AUTOSAR XML (schema 4-2-2)
package /STELLANTIS/EPT/ASWCs
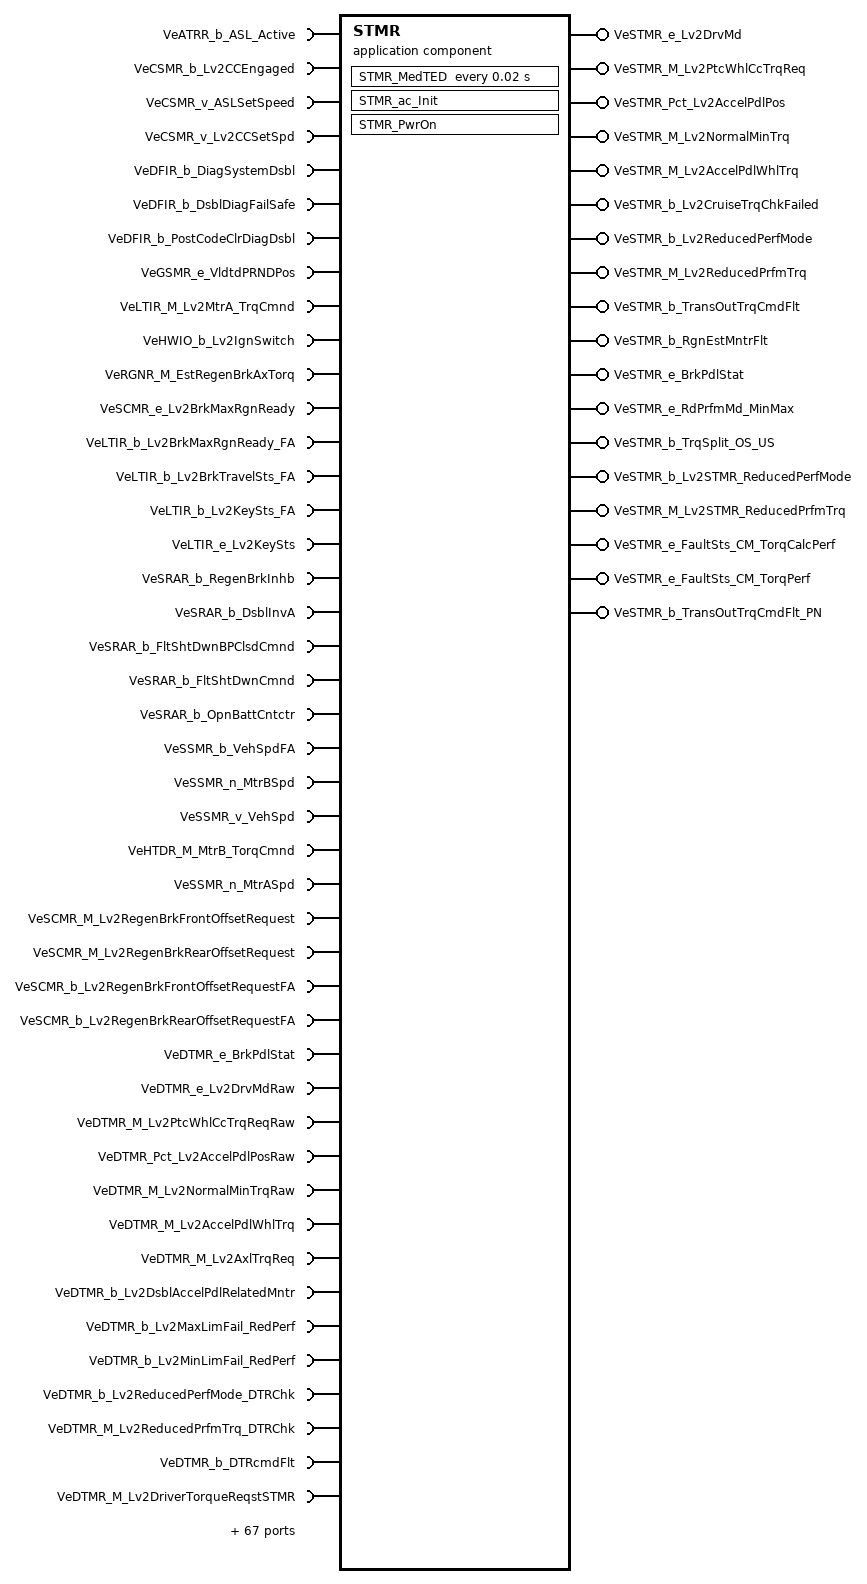
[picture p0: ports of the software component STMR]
  application sw component type STMR
    109 x require port:
      VeATRR_b_ASL_Active: nonqueued-receiver-com-spec{data-element=Value, init-value=0}, required-interface=VeATRR_b_ASL_Active
      VeCSMR_b_Lv2CCEngaged: nonqueued-receiver-com-spec{data-element=Value, init-value=0}, required-interface=VeCSMR_b_Lv2CCEngaged
      VeCSMR_v_ASLSetSpeed: nonqueued-receiver-com-spec{data-element=Value, init-value=0}, required-interface=VeCSMR_v_ASLSetSpeed
      VeCSMR_v_Lv2CCSetSpd: nonqueued-receiver-com-spec{data-element=Value, init-value=0}, required-interface=VeCSMR_v_Lv2CCSetSpd
      VeDFIR_b_DiagSystemDsbl: nonqueued-receiver-com-spec{data-element=Value, init-value=0}, required-interface=VeDFIR_b_DiagSystemDsbl
      VeDFIR_b_DsblDiagFailSafe: nonqueued-receiver-com-spec{data-element=Value, init-value=0}, required-interface=VeDFIR_b_DsblDiagFailSafe
      VeDFIR_b_PostCodeClrDiagDsbl: nonqueued-receiver-com-spec{data-element=Value, init-value=0}, required-interface=VeDFIR_b_PostCodeClrDiagDsbl
      VeGSMR_e_VldtdPRNDPos: variation-point={short-label=vpVeGSMR_e_VldtdPRNDPos, sw-syscond=1}, nonqueued-receiver-com-spec{data-element=Value, init-value=CeGSMR_e_TransRangePark}, required-interface=VeGSMR_e_VldtdPRNDPos
      VeLTIR_M_Lv2MtrA_TrqCmnd: nonqueued-receiver-com-spec{data-element=Value, init-value=0}, required-interface=VeLTIR_M_Lv2MtrA_TrqCmnd
      VeHWIO_b_Lv2IgnSwitch: nonqueued-receiver-com-spec{data-element=Value, init-value=0}, required-interface=VeHWIO_b_Lv2IgnSwitch
      VeRGNR_M_EstRegenBrkAxTorq: nonqueued-receiver-com-spec{data-element=Value, init-value=0}, required-interface=VeRGNR_M_EstRegenBrkAxTorq
      VeSCMR_e_Lv2BrkMaxRgnReady: nonqueued-receiver-com-spec{data-element=Value, init-value=0}, required-interface=VeSCMR_e_Lv2BrkMaxRgnReady
      VeLTIR_b_Lv2BrkMaxRgnReady_FA: nonqueued-receiver-com-spec{data-element=Value, init-value=0}, required-interface=VeLTIR_b_Lv2BrkMaxRgnReady_FA
      VeLTIR_b_Lv2BrkTravelSts_FA: nonqueued-receiver-com-spec{data-element=Value, init-value=0}, required-interface=VeLTIR_b_Lv2BrkTravelSts_FA
      VeLTIR_b_Lv2KeySts_FA: nonqueued-receiver-com-spec{data-element=Value, init-value=0}, required-interface=VeLTIR_b_Lv2KeySts_FA
      VeLTIR_e_Lv2KeySts: nonqueued-receiver-com-spec{data-element=Value, init-value=CeLTIR_e_IGN_LK}, required-interface=VeLTIR_e_Lv2KeySts
      VeSRAR_b_RegenBrkInhb: nonqueued-receiver-com-spec{data-element=Value, init-value=0}, required-interface=VeSRAR_b_RegenBrkInhb
      VeSRAR_b_DsblInvA: nonqueued-receiver-com-spec{data-element=Value, init-value=0}, required-interface=VeSRAR_b_DsblInvA
      VeSRAR_b_FltShtDwnBPClsdCmnd: nonqueued-receiver-com-spec{data-element=Value, init-value=0}, required-interface=VeSRAR_b_FltShtDwnBPClsdCmnd
      VeSRAR_b_FltShtDwnCmnd: nonqueued-receiver-com-spec{data-element=Value, init-value=0}, required-interface=VeSRAR_b_FltShtDwnCmnd
      VeSRAR_b_OpnBattCntctr: nonqueued-receiver-com-spec{data-element=Value, init-value=0}, required-interface=VeSRAR_b_OpnBattCntctr
      VeSSMR_b_VehSpdFA: nonqueued-receiver-com-spec{data-element=Value, init-value=0}, required-interface=VeSSMR_b_VehSpdFA
      VeSSMR_n_MtrBSpd: nonqueued-receiver-com-spec{data-element=Value, init-value=0}, required-interface=VeSSMR_n_MtrBSpd
      VeSSMR_v_VehSpd: nonqueued-receiver-com-spec{data-element=Value, init-value=0}, required-interface=VeSSMR_v_VehSpd
      VeHTDR_M_MtrB_TorqCmnd: nonqueued-receiver-com-spec{data-element=Value, init-value=0}, required-interface=VeHTDR_M_MtrB_TorqCmnd
      VeSSMR_n_MtrASpd: nonqueued-receiver-com-spec{data-element=Value, init-value=0}, required-interface=VeSSMR_n_MtrASpd
      VeSCMR_M_Lv2RegenBrkFrontOffsetRequest: nonqueued-receiver-com-spec{data-element=Value, init-value=0}, required-interface=VeSCMR_M_Lv2RegenBrkFrontOffsetRequest
      VeSCMR_M_Lv2RegenBrkRearOffsetRequest: nonqueued-receiver-com-spec{data-element=Value, init-value=0}, required-interface=VeSCMR_M_Lv2RegenBrkRearOffsetRequest
      VeSCMR_b_Lv2RegenBrkFrontOffsetRequestFA: nonqueued-receiver-com-spec{data-element=Value, init-value=0}, required-interface=VeSCMR_b_Lv2RegenBrkFrontOffsetRequestFA
      VeSCMR_b_Lv2RegenBrkRearOffsetRequestFA: nonqueued-receiver-com-spec{data-element=Value, init-value=0}, required-interface=VeSCMR_b_Lv2RegenBrkRearOffsetRequestFA
      VeDTMR_e_BrkPdlStat: nonqueued-receiver-com-spec{data-element=Value, init-value=CeSTMR_e_BrkStat_NotDtrmnd}, required-interface=VeDTMR_e_BrkPdlStat
      VeDTMR_e_Lv2DrvMdRaw: nonqueued-receiver-com-spec{data-element=Value, init-value=CeSTMR_e_DrvMdM182_Auto}, required-interface=VeDTMR_e_Lv2DrvMdRaw
      VeDTMR_M_Lv2PtcWhlCcTrqReqRaw: nonqueued-receiver-com-spec{data-element=Value, init-value=0}, required-interface=VeDTMR_M_Lv2PtcWhlCcTrqReqRaw
      VeDTMR_Pct_Lv2AccelPdlPosRaw: nonqueued-receiver-com-spec{data-element=Value, init-value=0}, required-interface=VeDTMR_Pct_Lv2AccelPdlPosRaw
      VeDTMR_M_Lv2NormalMinTrqRaw: nonqueued-receiver-com-spec{data-element=Value, init-value=0}, required-interface=VeDTMR_M_Lv2NormalMinTrqRaw
      VeDTMR_M_Lv2AccelPdlWhlTrq: nonqueued-receiver-com-spec{data-element=Value, init-value=0}, required-interface=VeDTMR_M_Lv2AccelPdlWhlTrq
      VeDTMR_M_Lv2AxlTrqReq: nonqueued-receiver-com-spec{data-element=Value, init-value=0}, required-interface=VeDTMR_M_Lv2AxlTrqReq
      VeDTMR_b_Lv2DsblAccelPdlRelatedMntr: nonqueued-receiver-com-spec{data-element=Value, init-value=0}, required-interface=VeDTMR_b_Lv2DsblAccelPdlRelatedMntr
      VeDTMR_b_Lv2MaxLimFail_RedPerf: nonqueued-receiver-com-spec{data-element=Value, init-value=0}, required-interface=VeDTMR_b_Lv2MaxLimFail_RedPerf
      VeDTMR_b_Lv2MinLimFail_RedPerf: nonqueued-receiver-com-spec{data-element=Value, init-value=0}, required-interface=VeDTMR_b_Lv2MinLimFail_RedPerf
      VeDTMR_b_Lv2ReducedPerfMode_DTRChk: nonqueued-receiver-com-spec{data-element=Value, init-value=0}, required-interface=VeDTMR_b_Lv2ReducedPerfMode_DTRChk
      VeDTMR_M_Lv2ReducedPrfmTrq_DTRChk: nonqueued-receiver-com-spec{data-element=Value, init-value=0}, required-interface=VeDTMR_M_Lv2ReducedPrfmTrq_DTRChk
      VeDTMR_b_DTRcmdFlt: nonqueued-receiver-com-spec{data-element=Value, init-value=0}, required-interface=VeDTMR_b_DTRcmdFlt
      VeDTMR_M_Lv2DriverTorqueReqstSTMR: nonqueued-receiver-com-spec{data-element=Value, init-value=0}, required-interface=VeDTMR_M_Lv2DriverTorqueReqstSTMR
      VeLTIR_b_Lv2RgnBrkAxTrqReq_FA: nonqueued-receiver-com-spec{data-element=Value, init-value=0}, required-interface=VeLTIR_b_Lv2RgnBrkAxTrqReq_FA
      VeSCMR_M_Lv2RgnBrkAxTrqReq: nonqueued-receiver-com-spec{data-element=Value, init-value=0}, required-interface=VeSCMR_M_Lv2RgnBrkAxTrqReq
      VeDTMR_b_VehIn_Lv2LashCntrl: variation-point={short-label=vpVeDTMR_b_VehIn_Lv2LashCntrl, sw-syscond=1}, nonqueued-receiver-com-spec{data-element=Value, init-value=0}, required-interface=VeDTMR_b_VehIn_Lv2LashCntrl
      VeSCCR_M_FrntAxlAdhMax: variation-point={short-label=vpVeSCCR_M_FrntAxlAdhMax, sw-syscond=1}, nonqueued-receiver-com-spec{data-element=Value, init-value=0}, required-interface=VeSCCR_M_FrntAxlAdhMax
      VeSCCR_M_RrAxlAdhMax: variation-point={short-label=vpVeSCCR_M_RrAxlAdhMax, sw-syscond=1}, nonqueued-receiver-com-spec{data-element=Value, init-value=0}, required-interface=VeSCCR_M_RrAxlAdhMax
      VeSCCR_M_FrntAxlAdhMin: variation-point={short-label=vpVeSCCR_M_FrntAxlAdhMin, sw-syscond=1}, nonqueued-receiver-com-spec{data-element=Value, init-value=0}, required-interface=VeSCCR_M_FrntAxlAdhMin
      VeSCCR_M_RrAxlAdhMin: variation-point={short-label=vpVeSCCR_M_RrAxlAdhMin, sw-syscond=1}, nonqueued-receiver-com-spec{data-element=Value, init-value=0}, required-interface=VeSCCR_M_RrAxlAdhMin
      VeSCMR_b_Lv2FrntAxlMaxRq_BSM: nonqueued-receiver-com-spec{data-element=Value, init-value=0}, required-interface=VeSCMR_b_Lv2FrntAxlMaxRq_BSM
      VeSCMR_b_Lv2FrntAxlMinRq_BSM: nonqueued-receiver-com-spec{data-element=Value, init-value=0}, required-interface=VeSCMR_b_Lv2FrntAxlMinRq_BSM
      VeSCMR_M_Lv2FrntAxlRq_BSM: nonqueued-receiver-com-spec{data-element=Value, init-value=0}, required-interface=VeSCMR_M_Lv2FrntAxlRq_BSM
      VeLTIR_b_Lv2FrntAxlRq_BSM_FA: nonqueued-receiver-com-spec{data-element=Value, init-value=0}, required-interface=VeLTIR_b_Lv2FrntAxlRq_BSM_FA
      VeSCMR_b_Lv2RrAxlMaxRq_BSM: nonqueued-receiver-com-spec{data-element=Value, init-value=0}, required-interface=VeSCMR_b_Lv2RrAxlMaxRq_BSM
      VeSCMR_b_Lv2RrAxlMinRq_BSM: nonqueued-receiver-com-spec{data-element=Value, init-value=0}, required-interface=VeSCMR_b_Lv2RrAxlMinRq_BSM
      VeSCMR_M_Lv2RrAxlRq_BSM: nonqueued-receiver-com-spec{data-element=Value, init-value=0}, required-interface=VeSCMR_M_Lv2RrAxlRq_BSM
      VeLTIR_b_Lv2RrAxlRq_BSM_FA: nonqueued-receiver-com-spec{data-element=Value, init-value=0}, required-interface=VeLTIR_b_Lv2RrAxlRq_BSM_FA
      VeSCCR_M_FrntAxlMaxRqPrtctd: variation-point={short-label=vpVeSCCR_M_FrntAxlMaxRqPrtctd, sw-syscond=1}, nonqueued-receiver-com-spec{data-element=Value, init-value=0}, required-interface=VeSCCR_M_FrntAxlMaxRqPrtctd
      VeSCCR_M_FrntAxlMinRqPrtctd: variation-point={short-label=vpVeSCCR_M_FrntAxlMinRqPrtctd, sw-syscond=1}, nonqueued-receiver-com-spec{data-element=Value, init-value=0}, required-interface=VeSCCR_M_FrntAxlMinRqPrtctd
      VeSRMR_e_LimitationMd: variation-point={short-label=vpVeSRMR_e_LimitationMd, sw-syscond=1}, nonqueued-receiver-com-spec{data-element=Value, init-value=CeSRMR_e_NoLimitation}, required-interface=VeSRMR_e_LimitationMd
      VeSCMR_b_Lv2FrntAxlMaxRqCANC2_BSM: nonqueued-receiver-com-spec{data-element=Value, init-value=0}, required-interface=VeSCMR_b_Lv2FrntAxlMaxRqCANC2_BSM
      VeSCMR_b_Lv2FrntAxlMinRqCANC2_BSM: nonqueued-receiver-com-spec{data-element=Value, init-value=0}, required-interface=VeSCMR_b_Lv2FrntAxlMinRqCANC2_BSM
      VeSCMR_M_Lv2FrntAxlRqCANC2_BSM: nonqueued-receiver-com-spec{data-element=Value, init-value=0}, required-interface=VeSCMR_M_Lv2FrntAxlRqCANC2_BSM
      VeLTIR_b_Lv2FrntAxlRqCANC2_BSM_FA: nonqueued-receiver-com-spec{data-element=Value, init-value=0}, required-interface=VeLTIR_b_Lv2FrntAxlRqCANC2_BSM_FA
      VeSCMR_b_Lv2RrAxlMaxRqCANC2_BSM: nonqueued-receiver-com-spec{data-element=Value, init-value=0}, required-interface=VeSCMR_b_Lv2RrAxlMaxRqCANC2_BSM
      VeSCMR_b_Lv2RrAxlMinRqCANC2_BSM: nonqueued-receiver-com-spec{data-element=Value, init-value=0}, required-interface=VeSCMR_b_Lv2RrAxlMinRqCANC2_BSM
      VeSCMR_M_Lv2RrAxlRqCANC2_BSM: nonqueued-receiver-com-spec{data-element=Value, init-value=0}, required-interface=VeSCMR_M_Lv2RrAxlRqCANC2_BSM
      VeLTIR_b_Lv2RrAxlRqCANC2_BSM_FA: nonqueued-receiver-com-spec{data-element=Value, init-value=0}, required-interface=VeLTIR_b_Lv2RrAxlRqCANC2_BSM_FA
      VeSSMR_n_EngSpd: nonqueued-receiver-com-spec{data-element=Value, init-value=0}, required-interface=VeSSMR_n_EngSpd
      VeSSMR_b_MtrBSpdFA: nonqueued-receiver-com-spec{data-element=Value, init-value=0}, required-interface=VeSSMR_b_MtrBSpdFA
      VeSSMR_b_EngSpdFA: nonqueued-receiver-com-spec{data-element=Value, init-value=0}, required-interface=VeSSMR_b_EngSpdFA
      VeSSMR_n_TurbSpd: nonqueued-receiver-com-spec{data-element=Value, init-value=0}, required-interface=VeSSMR_n_TurbSpd
      VeSCMR_b_EngActStdyStTorqFA: nonqueued-receiver-com-spec{data-element=Value, init-value=0}, required-interface=VeSCMR_b_EngActStdyStTorqFA
      VeSCMR_M_Lv2EngActStdyStTorq: nonqueued-receiver-com-spec{data-element=Value, init-value=0}, required-interface=VeSCMR_M_Lv2EngActStdyStTorq
      VeWTAR_M_AeCoastTorqDiff: nonqueued-receiver-com-spec{data-element=Value, init-value=0}, required-interface=VeWTAR_M_AeCoastTorqDiff
      VeWTAR_b_AeCoastTorqDiffActv: nonqueued-receiver-com-spec{data-element=Value, init-value=0}, required-interface=VeWTAR_b_AeCoastTorqDiffActv
      VeSCMR_e_Lv2TcaseRange_Stat: nonqueued-receiver-com-spec{data-element=Value, init-value=0}, required-interface=VeSCMR_e_Lv2TcaseRange_Stat
      VeSCMR_b_Lv2TcaseRange_StatFA: nonqueued-receiver-com-spec{data-element=Value, init-value=0}, required-interface=VeSCMR_b_Lv2TcaseRange_StatFA
      VeSCMR_e_Lv2Tcase_StatCANC: nonqueued-receiver-com-spec{data-element=Value, init-value=0}, required-interface=VeSCMR_e_Lv2Tcase_StatCANC
      VeSCMR_b_Lv2Tcase_StatCANCFA: nonqueued-receiver-com-spec{data-element=Value, init-value=0}, required-interface=VeSCMR_b_Lv2Tcase_StatCANCFA
      VeSCMR_r_Lv2TorqueTransRatio: nonqueued-receiver-com-spec{data-element=Value, init-value=0}, required-interface=VeSCMR_r_Lv2TorqueTransRatio
      VeSCMR_r_DriveLineRatioEpt: nonqueued-receiver-com-spec{data-element=Value, init-value=0}, required-interface=VeSCMR_r_DriveLineRatioEpt
      VeSCMR_b_DriveLineRatioEptFA: nonqueued-receiver-com-spec{data-element=Value, init-value=0}, required-interface=VeSCMR_b_DriveLineRatioEptFA
      VePSMR_Pct_Lv2AccelPedalEffPosition: nonqueued-receiver-com-spec{data-element=Value, init-value=0}, required-interface=VePSMR_Pct_Lv2AccelPedalEffPosition
      VeSCMR_e_Lv2GearEngaged: nonqueued-receiver-com-spec{data-element=Value, init-value=0}, required-interface=VeSCMR_e_Lv2GearEngaged
      VeSSMR_b_TransOutSpdFA: nonqueued-receiver-com-spec{data-element=Value, init-value=0}, required-interface=VeSSMR_b_TransOutSpdFA
      VeSCMR_b_Lv2GearEngaged_FA: nonqueued-receiver-com-spec{data-element=Value, init-value=0}, required-interface=VeSCMR_b_Lv2GearEngaged_FA
      VeSSMR_b_TurbSpdFA: nonqueued-receiver-com-spec{data-element=Value, init-value=0}, required-interface=VeSSMR_b_TurbSpdFA
      VePSMR_b_Lv2AccelPdlPosFlt: nonqueued-receiver-com-spec{data-element=Value, init-value=0}, required-interface=VePSMR_b_Lv2AccelPdlPosFlt
      VeSCMR_e_Lv2SumFWIDFst: nonqueued-receiver-com-spec{data-element=Value, init-value=0}, required-interface=VeSCMR_e_Lv2SumFWIDFst
      VeSCMR_b_Lv2SumFWIDFst_FA: nonqueued-receiver-com-spec{data-element=Value, init-value=0}, required-interface=VeSCMR_b_Lv2SumFWIDFst_FA
      VeSCMR_e_Lv2SumFWIDSlw: nonqueued-receiver-com-spec{data-element=Value, init-value=0}, required-interface=VeSCMR_e_Lv2SumFWIDSlw
      VeSCMR_b_Lv2SumFWIDSlw_FA: nonqueued-receiver-com-spec{data-element=Value, init-value=0}, required-interface=VeSCMR_b_Lv2SumFWIDSlw_FA
      VeOHSR_e_ILEState: nonqueued-receiver-com-spec{data-element=Value, init-value=CeOHSR_e_NeutralState}, required-interface=VeOHSR_e_ILEState
      VeDMAB_y_StatusByte_CM_TorqPerf: nonqueued-receiver-com-spec{data-element=Value, init-value=0}, required-interface=VeDMAB_y_StatusByte_CM_TorqPerf
      VeSCMR_n_Lv2WhlFL_Spd: variation-point={short-label=vpVeSCMR_n_Lv2WhlFL_Spd, sw-syscond=1}, nonqueued-receiver-com-spec{data-element=Value, init-value=0}, required-interface=VeSCMR_n_Lv2WhlFL_Spd
      VeSCMR_n_Lv2WhlFR_Spd: variation-point={short-label=vpVeSCMR_n_Lv2WhlFR_Spd, sw-syscond=1}, nonqueued-receiver-com-spec{data-element=Value, init-value=0}, required-interface=VeSCMR_n_Lv2WhlFR_Spd
      VeSCMR_b_Lv2WhlFL_Spd_FA: variation-point={short-label=vpVeSCMR_b_Lv2WhlFL_Spd_FA, sw-syscond=1}, nonqueued-receiver-com-spec{data-element=Value, init-value=0}, required-interface=VeSCMR_b_Lv2WhlFL_Spd_FA
      VeSCMR_b_Lv2WhlFR_Spd_FA: variation-point={short-label=vpVeSCMR_b_Lv2WhlFR_Spd_FA, sw-syscond=1}, nonqueued-receiver-com-spec{data-element=Value, init-value=0}, required-interface=VeSCMR_b_Lv2WhlFR_Spd_FA
      VeRGNR_M_EstRegenAchvdAxleTorq_Frnt: nonqueued-receiver-com-spec{data-element=Value, init-value=0}, required-interface=VeRGNR_M_EstRegenAchvdAxleTorq_Frnt
      VeRGNR_M_EstRegenAchvdAxleTorq_Rear: nonqueued-receiver-com-spec{data-element=Value, init-value=0}, required-interface=VeRGNR_M_EstRegenAchvdAxleTorq_Rear
      VeADAR_e_LeftActuationStatus: variation-point={short-label=vpVeADAR_e_LeftActuationStatus, sw-syscond=1}, nonqueued-receiver-com-spec{data-element=Value, init-value=CeADAR_e_SS_Indeterminate}, required-interface=VeADAR_e_LeftActuationStatus
      VeADAR_e_RightActuationStatus: variation-point={short-label=vpVeADAR_e_RightActuationStatus, sw-syscond=1}, nonqueued-receiver-com-spec{data-element=Value, init-value=CeADAR_e_SS_Indeterminate}, required-interface=VeADAR_e_RightActuationStatus
      VeLTIR_n_Lv2WhlFL_RPS: variation-point={short-label=vpVeLTIR_n_Lv2WhlFL_RPS, sw-syscond=1}, nonqueued-receiver-com-spec{data-element=Value, init-value=0}, required-interface=VeLTIR_n_Lv2WhlFL_RPS
      VeLTIR_n_Lv2WhlFR_RPS: variation-point={short-label=vpVeLTIR_n_Lv2WhlFR_RPS, sw-syscond=1}, nonqueued-receiver-com-spec{data-element=Value, init-value=0}, required-interface=VeLTIR_n_Lv2WhlFR_RPS
      VeLTIR_b_Lv2WhlFL_RPS_Flt: variation-point={short-label=vpVeLTIR_b_Lv2WhlFL_RPS_Flt, sw-syscond=1}, nonqueued-receiver-com-spec{data-element=Value, init-value=0}, required-interface=VeLTIR_b_Lv2WhlFL_RPS_Flt
      VeLTIR_b_Lv2WhlFR_RPS_Flt: variation-point={short-label=vpVeLTIR_b_Lv2WhlFR_RPS_Flt, sw-syscond=1}, nonqueued-receiver-com-spec{data-element=Value, init-value=0}, required-interface=VeLTIR_b_Lv2WhlFR_RPS_Flt
    18 x provide port:
      VeSTMR_e_Lv2DrvMd: nonqueued-sender-com-spec{data-element=Value, init-value=CeSTMR_e_DrvMdM182_Auto}, provided-interface=VeSTMR_e_Lv2DrvMd
      VeSTMR_M_Lv2PtcWhlCcTrqReq: nonqueued-sender-com-spec{data-element=Value, init-value=0}, provided-interface=VeSTMR_M_Lv2PtcWhlCcTrqReq
      VeSTMR_Pct_Lv2AccelPdlPos: nonqueued-sender-com-spec{data-element=Value, init-value=0}, provided-interface=VeSTMR_Pct_Lv2AccelPdlPos
      VeSTMR_M_Lv2NormalMinTrq: nonqueued-sender-com-spec{data-element=Value, init-value=0}, provided-interface=VeSTMR_M_Lv2NormalMinTrq
      VeSTMR_M_Lv2AccelPdlWhlTrq: nonqueued-sender-com-spec{data-element=Value, init-value=0}, provided-interface=VeSTMR_M_Lv2AccelPdlWhlTrq
      VeSTMR_b_Lv2CruiseTrqChkFailed: nonqueued-sender-com-spec{data-element=Value, init-value=0}, provided-interface=VeSTMR_b_Lv2CruiseTrqChkFailed
      VeSTMR_b_Lv2ReducedPerfMode: nonqueued-sender-com-spec{data-element=Value, init-value=0}, provided-interface=VeSTMR_b_Lv2ReducedPerfMode
      VeSTMR_M_Lv2ReducedPrfmTrq: nonqueued-sender-com-spec{data-element=Value, init-value=0}, provided-interface=VeSTMR_M_Lv2ReducedPrfmTrq
      VeSTMR_b_TransOutTrqCmdFlt: nonqueued-sender-com-spec{data-element=Value, init-value=0}, provided-interface=VeSTMR_b_TransOutTrqCmdFlt
      VeSTMR_b_RgnEstMntrFlt: nonqueued-sender-com-spec{data-element=Value, init-value=0}, provided-interface=VeSTMR_b_RgnEstMntrFlt
      VeSTMR_e_BrkPdlStat: nonqueued-sender-com-spec{data-element=Value, init-value=CeSTMR_e_BrkStat_NotDtrmnd}, provided-interface=VeSTMR_e_BrkPdlStat
      VeSTMR_e_RdPrfmMd_MinMax: nonqueued-sender-com-spec{data-element=Value, init-value=CeSTMR_e_NoRdPerfmMdRq}, provided-interface=VeSTMR_e_RdPrfmMd_MinMax
      VeSTMR_b_TrqSplit_OS_US: nonqueued-sender-com-spec{data-element=Value, init-value=0}, provided-interface=VeSTMR_b_TrqSplit_OS_US
      VeSTMR_b_Lv2STMR_ReducedPerfMode: nonqueued-sender-com-spec{data-element=Value, init-value=0}, provided-interface=VeSTMR_b_Lv2STMR_ReducedPerfMode
      VeSTMR_M_Lv2STMR_ReducedPrfmTrq: nonqueued-sender-com-spec{data-element=Value, init-value=0}, provided-interface=VeSTMR_M_Lv2STMR_ReducedPrfmTrq
      VeSTMR_e_FaultSts_CM_TorqCalcPerf: nonqueued-sender-com-spec{data-element=Value, init-value=CeDFIB_e_Init}, provided-interface=VeSTMR_e_FaultSts_CM_TorqCalcPerf
      VeSTMR_e_FaultSts_CM_TorqPerf: nonqueued-sender-com-spec{data-element=Value, init-value=CeDFIB_e_Init}, provided-interface=VeSTMR_e_FaultSts_CM_TorqPerf
      VeSTMR_b_TransOutTrqCmdFlt_PN: nonqueued-sender-com-spec{data-element=Value, init-value=0}, provided-interface=VeSTMR_b_TransOutTrqCmdFlt_PN
    require port STMR_FastTEF_StartCheckpoint: client-com-spec=CheckpointReached, required-interface=WdgM_LocalSupervision
    require port STMR_FastTEF_StopCheckpoint: client-com-spec=CheckpointReached, required-interface=WdgM_LocalSupervision
    behavior IB_STMR: data-type-mapping=msADTtoIDTMapping, handle-termination-and-restart=NO-SUPPORT
      timing event Event_MedTED: start-on-event=STMR_MedTED, period=0.02
      init event Event_STMR_ac_Init: start-on-event=STMR_ac_Init
      init event Event_PwrOn: start-on-event=STMR_PwrOn
      runnable STMR_ac_Init
        data-send-points:
          5 x access:
            OUT_VeSTMR_e_Lv2DrvMd_Value: accessed-variable=VeSTMR_e_Lv2DrvMd.Value
            OUT_VeSTMR_e_BrkPdlStat_Value: accessed-variable=VeSTMR_e_BrkPdlStat.Value
            OUT_VeSTMR_e_RdPrfmMd_MinMax_Value: accessed-variable=VeSTMR_e_RdPrfmMd_MinMax.Value
            OUT_VeSTMR_e_FaultSts_CM_TorqCalcPerf_Value: accessed-variable=VeSTMR_e_FaultSts_CM_TorqCalcPerf.Value
            OUT_VeSTMR_e_FaultSts_CM_TorqPerf_Value: accessed-variable=VeSTMR_e_FaultSts_CM_TorqPerf.Value
      runnable STMR_MedTED
        data-receive-point-by-arguments:
          109 x access:
            IN_VeADAR_e_LeftActuationStatus_Value: accessed-variable=VeADAR_e_LeftActuationStatus.Value, variation-point={short-label=vpIN_VeADAR_e_LeftActuationStatus_Value, sw-syscond=1}
            IN_VeADAR_e_RightActuationStatus_Value: accessed-variable=VeADAR_e_RightActuationStatus.Value, variation-point={short-label=vpIN_VeADAR_e_RightActuationStatus_Value, sw-syscond=1}
            IN_VeATRR_b_ASL_Active_Value: accessed-variable=VeATRR_b_ASL_Active.Value
            IN_VeCSMR_b_Lv2CCEngaged_Value: accessed-variable=VeCSMR_b_Lv2CCEngaged.Value
            IN_VeCSMR_v_ASLSetSpeed_Value: accessed-variable=VeCSMR_v_ASLSetSpeed.Value
            IN_VeCSMR_v_Lv2CCSetSpd_Value: accessed-variable=VeCSMR_v_Lv2CCSetSpd.Value
            IN_VeDFIR_b_DiagSystemDsbl_Value: accessed-variable=VeDFIR_b_DiagSystemDsbl.Value
            IN_VeDFIR_b_DsblDiagFailSafe_Value: accessed-variable=VeDFIR_b_DsblDiagFailSafe.Value
            IN_VeDFIR_b_PostCodeClrDiagDsbl_Value: accessed-variable=VeDFIR_b_PostCodeClrDiagDsbl.Value
            IN_VeDMAB_y_StatusByte_CM_TorqPerf_Value: accessed-variable=VeDMAB_y_StatusByte_CM_TorqPerf.Value
            IN_VeDTMR_M_Lv2AccelPdlWhlTrq_Value: accessed-variable=VeDTMR_M_Lv2AccelPdlWhlTrq.Value
            IN_VeDTMR_M_Lv2AxlTrqReq_Value: accessed-variable=VeDTMR_M_Lv2AxlTrqReq.Value
            IN_VeDTMR_M_Lv2DriverTorqueReqstSTMR_Value: accessed-variable=VeDTMR_M_Lv2DriverTorqueReqstSTMR.Value
            IN_VeDTMR_M_Lv2NormalMinTrqRaw_Value: accessed-variable=VeDTMR_M_Lv2NormalMinTrqRaw.Value
            IN_VeDTMR_M_Lv2PtcWhlCcTrqReqRaw_Value: accessed-variable=VeDTMR_M_Lv2PtcWhlCcTrqReqRaw.Value
            IN_VeDTMR_M_Lv2ReducedPrfmTrq_DTRChk_Value: accessed-variable=VeDTMR_M_Lv2ReducedPrfmTrq_DTRChk.Value
            IN_VeDTMR_Pct_Lv2AccelPdlPosRaw_Value: accessed-variable=VeDTMR_Pct_Lv2AccelPdlPosRaw.Value
            IN_VeDTMR_b_DTRcmdFlt_Value: accessed-variable=VeDTMR_b_DTRcmdFlt.Value
            IN_VeDTMR_b_Lv2DsblAccelPdlRelatedMntr_Value: accessed-variable=VeDTMR_b_Lv2DsblAccelPdlRelatedMntr.Value
            IN_VeDTMR_b_Lv2MaxLimFail_RedPerf_Value: accessed-variable=VeDTMR_b_Lv2MaxLimFail_RedPerf.Value
            IN_VeDTMR_b_Lv2MinLimFail_RedPerf_Value: accessed-variable=VeDTMR_b_Lv2MinLimFail_RedPerf.Value
            IN_VeDTMR_b_Lv2ReducedPerfMode_DTRChk_Value: accessed-variable=VeDTMR_b_Lv2ReducedPerfMode_DTRChk.Value
            IN_VeDTMR_b_VehIn_Lv2LashCntrl_Value: accessed-variable=VeDTMR_b_VehIn_Lv2LashCntrl.Value, variation-point={short-label=vpIN_VeDTMR_b_VehIn_Lv2LashCntrl_Value, sw-syscond=1}
            IN_VeDTMR_e_BrkPdlStat_Value: accessed-variable=VeDTMR_e_BrkPdlStat.Value
            IN_VeDTMR_e_Lv2DrvMdRaw_Value: accessed-variable=VeDTMR_e_Lv2DrvMdRaw.Value
            IN_VeGSMR_e_VldtdPRNDPos_Value: accessed-variable=VeGSMR_e_VldtdPRNDPos.Value, variation-point={short-label=vpIN_VeGSMR_e_VldtdPRNDPos_Value, sw-syscond=1}
            IN_VeHTDR_M_MtrB_TorqCmnd_Value: accessed-variable=VeHTDR_M_MtrB_TorqCmnd.Value
            IN_VeHWIO_b_Lv2IgnSwitch_Value: accessed-variable=VeHWIO_b_Lv2IgnSwitch.Value
            IN_VeLTIR_M_Lv2MtrA_TrqCmnd_Value: accessed-variable=VeLTIR_M_Lv2MtrA_TrqCmnd.Value
            IN_VeLTIR_b_Lv2BrkMaxRgnReady_FA_Value: accessed-variable=VeLTIR_b_Lv2BrkMaxRgnReady_FA.Value
            IN_VeLTIR_b_Lv2BrkTravelSts_FA_Value: accessed-variable=VeLTIR_b_Lv2BrkTravelSts_FA.Value
            IN_VeLTIR_b_Lv2FrntAxlRqCANC2_BSM_FA_Value: accessed-variable=VeLTIR_b_Lv2FrntAxlRqCANC2_BSM_FA.Value
            IN_VeLTIR_b_Lv2FrntAxlRq_BSM_FA_Value: accessed-variable=VeLTIR_b_Lv2FrntAxlRq_BSM_FA.Value
            IN_VeLTIR_b_Lv2KeySts_FA_Value: accessed-variable=VeLTIR_b_Lv2KeySts_FA.Value
            IN_VeLTIR_b_Lv2RgnBrkAxTrqReq_FA_Value: accessed-variable=VeLTIR_b_Lv2RgnBrkAxTrqReq_FA.Value
            IN_VeLTIR_b_Lv2RrAxlRqCANC2_BSM_FA_Value: accessed-variable=VeLTIR_b_Lv2RrAxlRqCANC2_BSM_FA.Value
            IN_VeLTIR_b_Lv2RrAxlRq_BSM_FA_Value: accessed-variable=VeLTIR_b_Lv2RrAxlRq_BSM_FA.Value
            IN_VeLTIR_b_Lv2WhlFL_RPS_Flt_Value: accessed-variable=VeLTIR_b_Lv2WhlFL_RPS_Flt.Value, variation-point={short-label=vpIN_VeLTIR_b_Lv2WhlFL_RPS_Flt_Value, sw-syscond=1}
            IN_VeLTIR_b_Lv2WhlFR_RPS_Flt_Value: accessed-variable=VeLTIR_b_Lv2WhlFR_RPS_Flt.Value, variation-point={short-label=vpIN_VeLTIR_b_Lv2WhlFR_RPS_Flt_Value, sw-syscond=1}
            IN_VeLTIR_e_Lv2KeySts_Value: accessed-variable=VeLTIR_e_Lv2KeySts.Value
            IN_VeLTIR_n_Lv2WhlFL_RPS_Value: accessed-variable=VeLTIR_n_Lv2WhlFL_RPS.Value, variation-point={short-label=vpIN_VeLTIR_n_Lv2WhlFL_RPS_Value, sw-syscond=1}
            IN_VeLTIR_n_Lv2WhlFR_RPS_Value: accessed-variable=VeLTIR_n_Lv2WhlFR_RPS.Value, variation-point={short-label=vpIN_VeLTIR_n_Lv2WhlFR_RPS_Value, sw-syscond=1}
            IN_VeOHSR_e_ILEState_Value: accessed-variable=VeOHSR_e_ILEState.Value
            IN_VePSMR_Pct_Lv2AccelPedalEffPosition_Value: accessed-variable=VePSMR_Pct_Lv2AccelPedalEffPosition.Value
            IN_VePSMR_b_Lv2AccelPdlPosFlt_Value: accessed-variable=VePSMR_b_Lv2AccelPdlPosFlt.Value
            IN_VeRGNR_M_EstRegenAchvdAxleTorq_Frnt_Value: accessed-variable=VeRGNR_M_EstRegenAchvdAxleTorq_Frnt.Value
            IN_VeRGNR_M_EstRegenAchvdAxleTorq_Rear_Value: accessed-variable=VeRGNR_M_EstRegenAchvdAxleTorq_Rear.Value
            IN_VeRGNR_M_EstRegenBrkAxTorq_Value: accessed-variable=VeRGNR_M_EstRegenBrkAxTorq.Value
            IN_VeSCCR_M_FrntAxlAdhMax_Value: accessed-variable=VeSCCR_M_FrntAxlAdhMax.Value, variation-point={short-label=vpIN_VeSCCR_M_FrntAxlAdhMax_Value, sw-syscond=1}
            IN_VeSCCR_M_FrntAxlAdhMin_Value: accessed-variable=VeSCCR_M_FrntAxlAdhMin.Value, variation-point={short-label=vpIN_VeSCCR_M_FrntAxlAdhMin_Value, sw-syscond=1}
            IN_VeSCCR_M_FrntAxlMaxRqPrtctd_Value: accessed-variable=VeSCCR_M_FrntAxlMaxRqPrtctd.Value, variation-point={short-label=vpIN_VeSCCR_M_FrntAxlMaxRqPrtctd_Value, sw-syscond=1}
            IN_VeSCCR_M_FrntAxlMinRqPrtctd_Value: accessed-variable=VeSCCR_M_FrntAxlMinRqPrtctd.Value, variation-point={short-label=vpIN_VeSCCR_M_FrntAxlMinRqPrtctd_Value, sw-syscond=1}
            IN_VeSCCR_M_RrAxlAdhMax_Value: accessed-variable=VeSCCR_M_RrAxlAdhMax.Value, variation-point={short-label=vpIN_VeSCCR_M_RrAxlAdhMax_Value, sw-syscond=1}
            IN_VeSCCR_M_RrAxlAdhMin_Value: accessed-variable=VeSCCR_M_RrAxlAdhMin.Value, variation-point={short-label=vpIN_VeSCCR_M_RrAxlAdhMin_Value, sw-syscond=1}
            IN_VeSCMR_M_Lv2EngActStdyStTorq_Value: accessed-variable=VeSCMR_M_Lv2EngActStdyStTorq.Value
            IN_VeSCMR_M_Lv2FrntAxlRqCANC2_BSM_Value: accessed-variable=VeSCMR_M_Lv2FrntAxlRqCANC2_BSM.Value
            IN_VeSCMR_M_Lv2FrntAxlRq_BSM_Value: accessed-variable=VeSCMR_M_Lv2FrntAxlRq_BSM.Value
            IN_VeSCMR_M_Lv2RegenBrkFrontOffsetRequest_Value: accessed-variable=VeSCMR_M_Lv2RegenBrkFrontOffsetRequest.Value
            IN_VeSCMR_M_Lv2RegenBrkRearOffsetRequest_Value: accessed-variable=VeSCMR_M_Lv2RegenBrkRearOffsetRequest.Value
            IN_VeSCMR_M_Lv2RgnBrkAxTrqReq_Value: accessed-variable=VeSCMR_M_Lv2RgnBrkAxTrqReq.Value
            IN_VeSCMR_M_Lv2RrAxlRqCANC2_BSM_Value: accessed-variable=VeSCMR_M_Lv2RrAxlRqCANC2_BSM.Value
            IN_VeSCMR_M_Lv2RrAxlRq_BSM_Value: accessed-variable=VeSCMR_M_Lv2RrAxlRq_BSM.Value
            IN_VeSCMR_b_DriveLineRatioEptFA_Value: accessed-variable=VeSCMR_b_DriveLineRatioEptFA.Value
            IN_VeSCMR_b_EngActStdyStTorqFA_Value: accessed-variable=VeSCMR_b_EngActStdyStTorqFA.Value
            IN_VeSCMR_b_Lv2FrntAxlMaxRqCANC2_BSM_Value: accessed-variable=VeSCMR_b_Lv2FrntAxlMaxRqCANC2_BSM.Value
            IN_VeSCMR_b_Lv2FrntAxlMaxRq_BSM_Value: accessed-variable=VeSCMR_b_Lv2FrntAxlMaxRq_BSM.Value
            IN_VeSCMR_b_Lv2FrntAxlMinRqCANC2_BSM_Value: accessed-variable=VeSCMR_b_Lv2FrntAxlMinRqCANC2_BSM.Value
            IN_VeSCMR_b_Lv2FrntAxlMinRq_BSM_Value: accessed-variable=VeSCMR_b_Lv2FrntAxlMinRq_BSM.Value
            IN_VeSCMR_b_Lv2GearEngaged_FA_Value: accessed-variable=VeSCMR_b_Lv2GearEngaged_FA.Value
            IN_VeSCMR_b_Lv2RegenBrkFrontOffsetRequestFA_Value: accessed-variable=VeSCMR_b_Lv2RegenBrkFrontOffsetRequestFA.Value
            IN_VeSCMR_b_Lv2RegenBrkRearOffsetRequestFA_Value: accessed-variable=VeSCMR_b_Lv2RegenBrkRearOffsetRequestFA.Value
            IN_VeSCMR_b_Lv2RrAxlMaxRqCANC2_BSM_Value: accessed-variable=VeSCMR_b_Lv2RrAxlMaxRqCANC2_BSM.Value
            IN_VeSCMR_b_Lv2RrAxlMaxRq_BSM_Value: accessed-variable=VeSCMR_b_Lv2RrAxlMaxRq_BSM.Value
            IN_VeSCMR_b_Lv2RrAxlMinRqCANC2_BSM_Value: accessed-variable=VeSCMR_b_Lv2RrAxlMinRqCANC2_BSM.Value
            IN_VeSCMR_b_Lv2RrAxlMinRq_BSM_Value: accessed-variable=VeSCMR_b_Lv2RrAxlMinRq_BSM.Value
            IN_VeSCMR_b_Lv2SumFWIDFst_FA_Value: accessed-variable=VeSCMR_b_Lv2SumFWIDFst_FA.Value
            IN_VeSCMR_b_Lv2SumFWIDSlw_FA_Value: accessed-variable=VeSCMR_b_Lv2SumFWIDSlw_FA.Value
            IN_VeSCMR_b_Lv2TcaseRange_StatFA_Value: accessed-variable=VeSCMR_b_Lv2TcaseRange_StatFA.Value
            IN_VeSCMR_b_Lv2Tcase_StatCANCFA_Value: accessed-variable=VeSCMR_b_Lv2Tcase_StatCANCFA.Value
            IN_VeSCMR_b_Lv2WhlFL_Spd_FA_Value: accessed-variable=VeSCMR_b_Lv2WhlFL_Spd_FA.Value, variation-point={short-label=vpIN_VeSCMR_b_Lv2WhlFL_Spd_FA_Value, sw-syscond=1}
            IN_VeSCMR_b_Lv2WhlFR_Spd_FA_Value: accessed-variable=VeSCMR_b_Lv2WhlFR_Spd_FA.Value, variation-point={short-label=vpIN_VeSCMR_b_Lv2WhlFR_Spd_FA_Value, sw-syscond=1}
            IN_VeSCMR_e_Lv2BrkMaxRgnReady_Value: accessed-variable=VeSCMR_e_Lv2BrkMaxRgnReady.Value
            IN_VeSCMR_e_Lv2GearEngaged_Value: accessed-variable=VeSCMR_e_Lv2GearEngaged.Value
            IN_VeSCMR_e_Lv2SumFWIDFst_Value: accessed-variable=VeSCMR_e_Lv2SumFWIDFst.Value
            IN_VeSCMR_e_Lv2SumFWIDSlw_Value: accessed-variable=VeSCMR_e_Lv2SumFWIDSlw.Value
            IN_VeSCMR_e_Lv2TcaseRange_Stat_Value: accessed-variable=VeSCMR_e_Lv2TcaseRange_Stat.Value
            IN_VeSCMR_e_Lv2Tcase_StatCANC_Value: accessed-variable=VeSCMR_e_Lv2Tcase_StatCANC.Value
            IN_VeSCMR_n_Lv2WhlFL_Spd_Value: accessed-variable=VeSCMR_n_Lv2WhlFL_Spd.Value, variation-point={short-label=vpIN_VeSCMR_n_Lv2WhlFL_Spd_Value, sw-syscond=1}
            IN_VeSCMR_n_Lv2WhlFR_Spd_Value: accessed-variable=VeSCMR_n_Lv2WhlFR_Spd.Value, variation-point={short-label=vpIN_VeSCMR_n_Lv2WhlFR_Spd_Value, sw-syscond=1}
            IN_VeSCMR_r_DriveLineRatioEpt_Value: accessed-variable=VeSCMR_r_DriveLineRatioEpt.Value
            IN_VeSCMR_r_Lv2TorqueTransRatio_Value: accessed-variable=VeSCMR_r_Lv2TorqueTransRatio.Value
            IN_VeSRAR_b_DsblInvA_Value: accessed-variable=VeSRAR_b_DsblInvA.Value
            IN_VeSRAR_b_FltShtDwnBPClsdCmnd_Value: accessed-variable=VeSRAR_b_FltShtDwnBPClsdCmnd.Value
            IN_VeSRAR_b_FltShtDwnCmnd_Value: accessed-variable=VeSRAR_b_FltShtDwnCmnd.Value
            IN_VeSRAR_b_OpnBattCntctr_Value: accessed-variable=VeSRAR_b_OpnBattCntctr.Value
            IN_VeSRAR_b_RegenBrkInhb_Value: accessed-variable=VeSRAR_b_RegenBrkInhb.Value
            IN_VeSRMR_e_LimitationMd_Value: accessed-variable=VeSRMR_e_LimitationMd.Value, variation-point={short-label=vpIN_VeSRMR_e_LimitationMd_Value, sw-syscond=1}
            IN_VeSSMR_b_EngSpdFA_Value: accessed-variable=VeSSMR_b_EngSpdFA.Value
            IN_VeSSMR_b_MtrBSpdFA_Value: accessed-variable=VeSSMR_b_MtrBSpdFA.Value
            IN_VeSSMR_b_TransOutSpdFA_Value: accessed-variable=VeSSMR_b_TransOutSpdFA.Value
            IN_VeSSMR_b_TurbSpdFA_Value: accessed-variable=VeSSMR_b_TurbSpdFA.Value
            IN_VeSSMR_b_VehSpdFA_Value: accessed-variable=VeSSMR_b_VehSpdFA.Value
            IN_VeSSMR_n_EngSpd_Value: accessed-variable=VeSSMR_n_EngSpd.Value
            IN_VeSSMR_n_MtrASpd_Value: accessed-variable=VeSSMR_n_MtrASpd.Value
            IN_VeSSMR_n_MtrBSpd_Value: accessed-variable=VeSSMR_n_MtrBSpd.Value
            IN_VeSSMR_n_TurbSpd_Value: accessed-variable=VeSSMR_n_TurbSpd.Value
            IN_VeSSMR_v_VehSpd_Value: accessed-variable=VeSSMR_v_VehSpd.Value
            IN_VeWTAR_M_AeCoastTorqDiff_Value: accessed-variable=VeWTAR_M_AeCoastTorqDiff.Value
            IN_VeWTAR_b_AeCoastTorqDiffActv_Value: accessed-variable=VeWTAR_b_AeCoastTorqDiffActv.Value
        data-send-points:
          18 x access:
            OUT_VeSTMR_b_Lv2CruiseTrqChkFailed_Value: accessed-variable=VeSTMR_b_Lv2CruiseTrqChkFailed.Value
            OUT_VeSTMR_b_Lv2ReducedPerfMode_Value: accessed-variable=VeSTMR_b_Lv2ReducedPerfMode.Value
            OUT_VeSTMR_M_Lv2ReducedPrfmTrq_Value: accessed-variable=VeSTMR_M_Lv2ReducedPrfmTrq.Value
            OUT_VeSTMR_b_TransOutTrqCmdFlt_Value: accessed-variable=VeSTMR_b_TransOutTrqCmdFlt.Value
            OUT_VeSTMR_b_RgnEstMntrFlt_Value: accessed-variable=VeSTMR_b_RgnEstMntrFlt.Value
            OUT_VeSTMR_b_TrqSplit_OS_US_Value: accessed-variable=VeSTMR_b_TrqSplit_OS_US.Value
            OUT_VeSTMR_b_Lv2STMR_ReducedPerfMode_Value: accessed-variable=VeSTMR_b_Lv2STMR_ReducedPerfMode.Value
            OUT_VeSTMR_M_Lv2STMR_ReducedPrfmTrq_Value: accessed-variable=VeSTMR_M_Lv2STMR_ReducedPrfmTrq.Value
            OUT_VeSTMR_e_Lv2DrvMd_Value: accessed-variable=VeSTMR_e_Lv2DrvMd.Value
            OUT_VeSTMR_M_Lv2PtcWhlCcTrqReq_Value: accessed-variable=VeSTMR_M_Lv2PtcWhlCcTrqReq.Value
            OUT_VeSTMR_Pct_Lv2AccelPdlPos_Value: accessed-variable=VeSTMR_Pct_Lv2AccelPdlPos.Value
            OUT_VeSTMR_M_Lv2NormalMinTrq_Value: accessed-variable=VeSTMR_M_Lv2NormalMinTrq.Value
            OUT_VeSTMR_M_Lv2AccelPdlWhlTrq_Value: accessed-variable=VeSTMR_M_Lv2AccelPdlWhlTrq.Value
            OUT_VeSTMR_e_BrkPdlStat_Value: accessed-variable=VeSTMR_e_BrkPdlStat.Value
            OUT_VeSTMR_e_RdPrfmMd_MinMax_Value: accessed-variable=VeSTMR_e_RdPrfmMd_MinMax.Value
            OUT_VeSTMR_e_FaultSts_CM_TorqCalcPerf_Value: accessed-variable=VeSTMR_e_FaultSts_CM_TorqCalcPerf.Value
            OUT_VeSTMR_e_FaultSts_CM_TorqPerf_Value: accessed-variable=VeSTMR_e_FaultSts_CM_TorqPerf.Value
            OUT_VeSTMR_b_TransOutTrqCmdFlt_PN_Value: accessed-variable=VeSTMR_b_TransOutTrqCmdFlt_PN.Value
        sync call SC_STMR_FastTEF_StartCheckpoint_CheckpointReached: operation=STMR_FastTEF_StartCheckpoint.CheckpointReached, timeout=1E-06
        sync call SC_STMR_FastTEF_StopCheckpoint_CheckpointReached: operation=STMR_FastTEF_StopCheckpoint.CheckpointReached, timeout=1E-06
      runnable STMR_PwrOn
        data-send-points:
          18 x access:
            OUT_VeSTMR_e_Lv2DrvMd_Value: accessed-variable=VeSTMR_e_Lv2DrvMd.Value
            OUT_VeSTMR_M_Lv2PtcWhlCcTrqReq_Value: accessed-variable=VeSTMR_M_Lv2PtcWhlCcTrqReq.Value
            OUT_VeSTMR_Pct_Lv2AccelPdlPos_Value: accessed-variable=VeSTMR_Pct_Lv2AccelPdlPos.Value
            OUT_VeSTMR_M_Lv2NormalMinTrq_Value: accessed-variable=VeSTMR_M_Lv2NormalMinTrq.Value
            OUT_VeSTMR_M_Lv2AccelPdlWhlTrq_Value: accessed-variable=VeSTMR_M_Lv2AccelPdlWhlTrq.Value
            OUT_VeSTMR_b_Lv2CruiseTrqChkFailed_Value: accessed-variable=VeSTMR_b_Lv2CruiseTrqChkFailed.Value
            OUT_VeSTMR_b_Lv2ReducedPerfMode_Value: accessed-variable=VeSTMR_b_Lv2ReducedPerfMode.Value
            OUT_VeSTMR_M_Lv2ReducedPrfmTrq_Value: accessed-variable=VeSTMR_M_Lv2ReducedPrfmTrq.Value
            OUT_VeSTMR_b_TransOutTrqCmdFlt_Value: accessed-variable=VeSTMR_b_TransOutTrqCmdFlt.Value
            OUT_VeSTMR_b_RgnEstMntrFlt_Value: accessed-variable=VeSTMR_b_RgnEstMntrFlt.Value
            OUT_VeSTMR_e_BrkPdlStat_Value: accessed-variable=VeSTMR_e_BrkPdlStat.Value
            OUT_VeSTMR_e_RdPrfmMd_MinMax_Value: accessed-variable=VeSTMR_e_RdPrfmMd_MinMax.Value
            OUT_VeSTMR_b_TrqSplit_OS_US_Value: accessed-variable=VeSTMR_b_TrqSplit_OS_US.Value
            OUT_VeSTMR_b_Lv2STMR_ReducedPerfMode_Value: accessed-variable=VeSTMR_b_Lv2STMR_ReducedPerfMode.Value
            OUT_VeSTMR_M_Lv2STMR_ReducedPrfmTrq_Value: accessed-variable=VeSTMR_M_Lv2STMR_ReducedPrfmTrq.Value
            OUT_VeSTMR_e_FaultSts_CM_TorqCalcPerf_Value: accessed-variable=VeSTMR_e_FaultSts_CM_TorqCalcPerf.Value
            OUT_VeSTMR_e_FaultSts_CM_TorqPerf_Value: accessed-variable=VeSTMR_e_FaultSts_CM_TorqPerf.Value
            OUT_VeSTMR_b_TransOutTrqCmdFlt_PN_Value: accessed-variable=VeSTMR_b_TransOutTrqCmdFlt_PN.Value
      4 x variation point proxy, all with category=CONDITION, condition-access=0:
        Variant_STMR_FUNC_{1..4}
